# PY32F031xx register map
Vendor: Puya; Series: PY32F0; File version: 1.0.0
CPU: CM0+ r0p1, little endian, no MPU, no FPU, 4 interrupt priority bits
Registers are 32-bit, read-write, reset 0x0 unless marked. A register's access mark holds for its fields unless they carry their own. Offsets are from the block's base; [hi:lo] are bit positions; {n}, {i} and the like mark numbered series; 'fields as' and 'values as' point back to an identical list.

## DMA — Direct memory access
Base 0x40020000
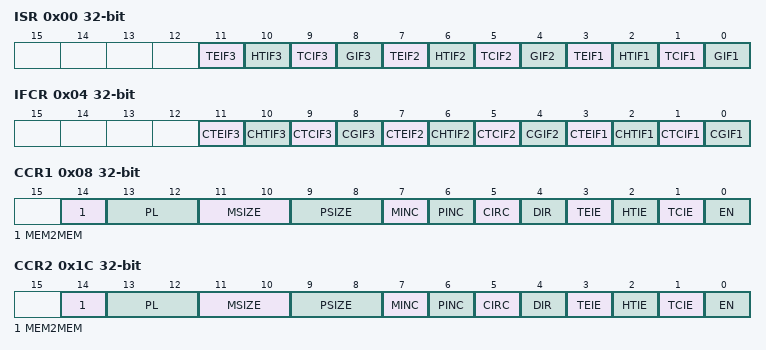
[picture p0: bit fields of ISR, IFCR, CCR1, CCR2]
0x00 ISR ro — DMA interrupt status register (DMA_ISR)
  [11] TEIF3 — Channel 3 Transfer Error flag
  [10] HTIF3 — Channel 3 Half Transfer Complete flag
  [9] TCIF3 — Channel 3 Transfer Complete flag
  [8] GIF3 — Channel 3 Global interrupt flag
  [7] TEIF2 — Channel 2 Transfer Error flag
  [6] HTIF2 — Channel 2 Half Transfer Complete flag
  [5] TCIF2 — Channel 2 Transfer Complete flag
  [4] GIF2 — Channel 2 Global interrupt flag
  [3] TEIF1 — Channel 1 Transfer Error flag
  [2] HTIF1 — Channel 1 Half Transfer Complete flag
  [1] TCIF1 — Channel 1 Transfer Complete flag
  [0] GIF1 — Channel 1 Global interrupt flag
0x04 IFCR wo — DMA interrupt flag clear register (DMA_IFCR)
  [11] CTEIF3 — Channel 3 Transfer Error clear
  [10] CHTIF3 — Channel 3 Half Transfer clear
  [9] CTCIF3 — Channel 3 Transfer Complete clear
  [8] CGIF3 — Channel 3 Global interrupt clear
  [7] CTEIF2 — Channel 2 Transfer Error clear
  [6] CHTIF2 — Channel 2 Half Transfer clear
  [5] CTCIF2 — Channel 2 Transfer Complete clear
  [4] CGIF2 — Channel 2 Global interrupt clear
  [3] CTEIF1 — Channel 1 Transfer Error clear
  [2] CHTIF1 — Channel 1 Half Transfer clear
  [1] CTCIF1 — Channel 1 Transfer Complete clear
  [0] CGIF1 — Channel 1 Global interrupt clear
0x08 CCR1 — DMA channel configuration register (DMA_CCR)
  [14] MEM2MEM — Memory to memory mode
  [13:12] PL — Channel Priority level
  [11:10] MSIZE — Memory size
  [9:8] PSIZE — Peripheral size
  [7] MINC — Memory increment mode
  [6] PINC — Peripheral increment mode
  [5] CIRC — Circular mode
  [4] DIR — Data transfer direction
  [3] TEIE — Transfer error interrupt enable
  [2] HTIE — Half Transfer interrupt enable
  [1] TCIE — Transfer complete interrupt enable
  [0] EN — Channel enable
0x0C CNDTR1 — DMA channel 1 number of data register
  [15:0] NDT — Number of data to transfer
0x10 CPAR1 — DMA channel 1 peripheral address register
  [31:0] PA — Peripheral address
{0x0+0x14*i} CMAR{i} (i=1..3) — DMA channel {i} memory address register
  [31:0] MA — Memory address
0x1C CCR2 — DMA channel configuration register (DMA_CCR)
  fields as CCR1
0x20 CNDTR2 — DMA channel 2 number of data register
  [15:0] NDT — Number of data to transfer
0x24 CPAR2 — DMA channel 2 peripheral address register
  [31:0] PA — Peripheral address
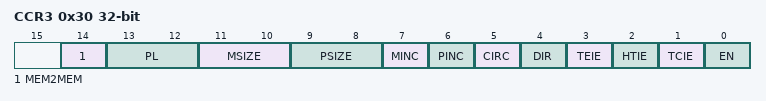
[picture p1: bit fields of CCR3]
0x30 CCR3 — DMA channel configuration register (DMA_CCR)
  fields as CCR1
0x34 CNDTR3 — DMA channel 3 number of data register
  [15:0] NDT — Number of data to transfer
0x38 CPAR3 — DMA channel 3 peripheral address register
  [31:0] PA — Peripheral address

## FLASH
Base 0x40022000
0x00 ACR reset 0x600 — Access control register
  [1:0] LATENCY
0x08 KEYR wo — Flash key register
  [31:0] KEY — Flash key
0x0C OPTKEYR wo — Option byte key register
  [31:0] OPTKEY — Option byte key
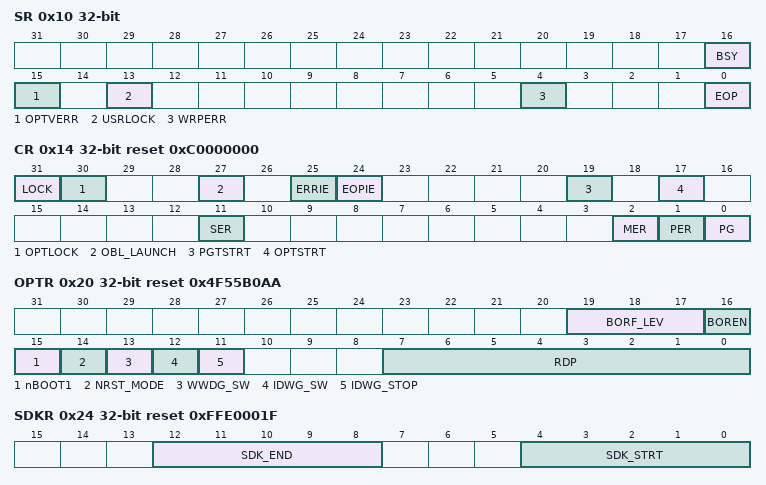
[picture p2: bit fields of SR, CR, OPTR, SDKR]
0x10 SR — Status register
  [16] BSY — Busy
  [15] OPTVERR — Option and Engineering bits loading validity error
  [13] USRLOCK — User data flash lock
  [4] WRPERR — Write protected error
  [0] EOP — End of operation
0x14 CR reset 0xC0000000 — Flash control register
  [31] LOCK — FLASH_CR Lock
  [30] OPTLOCK — Options Lock
  [27] OBL_LAUNCH — Force the option byte loading
  [25] ERRIE — Error interrupt enable
  [24] EOPIE — End of operation interrupt enable
  [19] PGTSTRT — Flash main memory program start
  [17] OPTSTRT — Option byte program start
  [11] SER — Sector erase
  [2] MER — Mass erase
  [1] PER — Page erase
  [0] PG — Programming
0x20 OPTR reset 0x4F55B0AA — Flash option register
  [19:17] BORF_LEV — These bits contain the VDD supply level threshold that activates the reset
  [16] BOREN — BOR reset Level
  [15] nBOOT1 — Boot configuration
  [14] NRST_MODE
  [13] WWDG_SW — Window watchdog selection
  [12] IDWG_SW — Independent watchdog selection
  [11] IDWG_STOP — Stop mode IWDG counter
  [7:0] RDP — Read Protection
0x24 SDKR reset 0xFFE0001F — Flash SDK address register
  [12:8] SDK_END — SDK area end address
  [4:0] SDK_STRT — SDK area start address
0x2C WRPR reset 0xFFFF — Flash WRP address register
  [15:0] WRP — WRP address
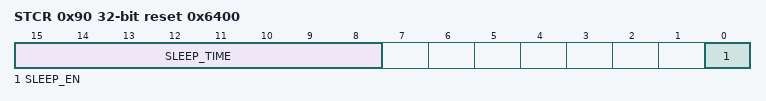
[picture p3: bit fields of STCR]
0x90 STCR reset 0x6400 — Flash sleep time config register
  [15:8] SLEEP_TIME — FLash sleep time configuration(counter based on HSI_10M)
  [0] SLEEP_EN — FLash sleep enable
0x100 TS0 reset 0xB4 — Flash TS0 register
  [7:0] TS0 — FLash TS0 register
0x104 TS1 reset 0x1B0 — Flash TS1 register
  [8:0] TS1 — FLash TS1 register
0x108 TS2P reset 0xB4 — Flash TS2P register
  [7:0] TS2P — FLash TS2P register
0x10C TPS3 reset 0x6C0 — Flash TPS3 register
  [10:0] TPS3 — FLash TPS3 register
0x110 TS3 reset 0xB4 — Flash TS3 register
  [7:0] TS3 — FLash TS3 register
0x114 PERTPE reset 0xEA60 — Flash PERTPE register
  [16:0] PERTPE — FLash PERTPE register
0x118 SMERTPE reset 0xFD20 — Flash SMERTPE register
  [16:0] SMERTPE — FLash SMERTPE register
0x11C PRGTPE reset 0x8CA0 — Flash PRGTPE register
  [15:0] PRGTPE — FLash PRGTPE register
0x120 PRETPE reset 0x12C0 — Flash PRETPE register
  [12:0] PRETPE — FLash PRETPE register
